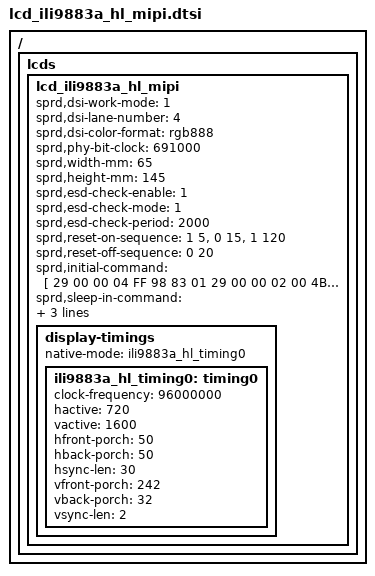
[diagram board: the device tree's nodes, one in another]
/ {
	fragment {
		target-path = "/";
		__overlay__ {
			lcds {
            lcd_ili9883a_hl_mipi: lcd_ili9883a_hl_mipi {
                sprd,dsi-work-mode = <1>;
                sprd,dsi-lane-number = <4>;
                sprd,dsi-color-format = "rgb888";
        
                sprd,phy-bit-clock = <691000>;
        
                sprd,width-mm = <65>;
                sprd,height-mm = <145>;
                sprd,esd-check-enable = <1>;
                sprd,esd-check-mode = <1>;
                sprd,esd-check-period = <2000>;
        
                sprd,reset-on-sequence = <1 5>, <0 15>, <1 120>;
                sprd,reset-off-sequence = <0 20>;
        
                sprd,initial-command = [
					29 00 00 04 FF 98 83 01 
					29 00 00 02 00 4B 
					29 00 00 02 01 34 
					29 00 00 02 02 58 
					29 00 00 02 03 5E 
					29 00 00 02 08 86 
					29 00 00 02 09 01 
					29 00 00 02 0A 73 
					29 00 00 02 0B 00 
					29 00 00 02 0C 0A 
					29 00 00 02 0D 0A 
					29 00 00 02 0E 00 
					29 00 00 02 0F 00 
					29 00 00 02 28 86 
					29 00 00 02 29 4D 
					29 00 00 02 31 07 
					29 00 00 02 32 00 
					29 00 00 02 33 26 
					29 00 00 02 34 02 
					29 00 00 02 35 09 
					29 00 00 02 36 0B 
					29 00 00 02 37 15 
					29 00 00 02 38 17 
					29 00 00 02 39 11 
					29 00 00 02 3A 13 
					29 00 00 02 3B 01 
					29 00 00 02 3C 2B 
					29 00 00 02 3D 07 
					29 00 00 02 3E 07 
					29 00 00 02 3F 07 
					29 00 00 02 40 07 
					29 00 00 02 41 07 
					29 00 00 02 42 07 
					29 00 00 02 43 07 
					29 00 00 02 44 07 
					29 00 00 02 45 07 
					29 00 00 02 46 07 
					29 00 00 02 47 07 
					29 00 00 02 48 00 
					29 00 00 02 49 26 
					29 00 00 02 4A 02 
					29 00 00 02 4B 08 
					29 00 00 02 4C 0A 
					29 00 00 02 4D 14 
					29 00 00 02 4E 16 
					29 00 00 02 4F 10 
					29 00 00 02 50 12 
					29 00 00 02 51 01 
					29 00 00 02 52 2B 
					29 00 00 02 53 07 
					29 00 00 02 54 07 
					29 00 00 02 55 07 
					29 00 00 02 56 07 
					29 00 00 02 57 07 
					29 00 00 02 58 07 
					29 00 00 02 59 07 
					29 00 00 02 5A 07 
					29 00 00 02 5B 07 
					29 00 00 02 5C 07 
					29 00 00 02 61 07 
					29 00 00 02 62 00 
					29 00 00 02 63 26 
					29 00 00 02 64 02 
					29 00 00 02 65 0A 
					29 00 00 02 66 08 
					29 00 00 02 67 12 
					29 00 00 02 68 10 
					29 00 00 02 69 16 
					29 00 00 02 6A 14 
					29 00 00 02 6B 01 
					29 00 00 02 6C 2B 
					29 00 00 02 6D 07 
					29 00 00 02 6E 07 
					29 00 00 02 6F 07 
					29 00 00 02 70 07 
					29 00 00 02 71 07 
					29 00 00 02 72 07 
					29 00 00 02 73 07 
					29 00 00 02 74 07 
					29 00 00 02 75 07 
					29 00 00 02 76 07 
					29 00 00 02 77 07 
					29 00 00 02 78 00 
					29 00 00 02 79 26 
					29 00 00 02 7A 02 
					29 00 00 02 7B 0B 
					29 00 00 02 7C 09 
					29 00 00 02 7D 13 
					29 00 00 02 7E 11 
					29 00 00 02 7F 17 
					29 00 00 02 80 15 
					29 00 00 02 81 01 
					29 00 00 02 82 2B 
					29 00 00 02 83 07 
					29 00 00 02 84 07 
					29 00 00 02 85 07 
					29 00 00 02 86 07 
					29 00 00 02 87 07 
					29 00 00 02 88 07 
					29 00 00 02 89 07 
					29 00 00 02 8A 07 
					29 00 00 02 8B 07 
					29 00 00 02 8C 07 
					29 00 00 02 B0 33 
					29 00 00 02 B1 33 
					29 00 00 02 B2 00 
					29 00 00 02 B9 10 
					29 00 00 02 BA 30 
					29 00 00 02 D0 01 
					29 00 00 02 D1 00 
					29 00 00 02 E2 00 
					29 00 00 02 E6 22 
					29 00 00 02 E7 54 
					29 00 00 04 FF 98 83 02 
					29 00 00 02 06 57 
					29 00 00 02 0A 5B 
					29 00 00 02 0C 00 
					29 00 00 02 0D 20 
					29 00 00 02 0E 73 
					29 00 00 02 39 05 
					29 00 00 02 3A 20 
					29 00 00 02 3B 73 
					29 00 00 02 3C 7C 
					29 00 00 02 F0 05 
					29 00 00 02 F1 5D 
					29 00 00 02 4A 00 
					29 00 00 02 4D CE 
					29 00 00 04 FF 98 83 05 
					29 00 00 02 03 00 
					29 00 00 02 04 B1 
					29 00 00 02 69 9C 
					29 00 00 02 6A 9C 
					29 00 00 02 6D 8D 
					29 00 00 02 73 93 
					29 00 00 02 79 C9 
					29 00 00 02 7F BB 
					29 00 00 04 FF 98 83 06 
					29 00 00 02 D9 1F 
					29 00 00 02 C0 40 
					29 00 00 02 C1 16 
					29 00 00 04 FF 98 83 08 
					29 00 00 1E E0 00 24 31 58 82 50 B9 E7 11 40 95 67 A6 D9 08 AA 35 63 9B BD FE E8 0C 3A 72 3F 9E CF EC 
					29 00 00 1E E1 00 24 31 58 82 50 B9 E7 11 40 95 67 A6 D9 08 AA 35 63 9B BD FE E8 0C 3A 72 3F 9E CF EC 
					29 00 00 04 FF 98 83 0B 
					29 00 00 02 9A 42 
					29 00 00 02 9B C5 
					29 00 00 02 9C 02 
					29 00 00 02 9D 02 
					29 00 00 02 9E 45 
					29 00 00 02 9F 45 
					29 00 00 02 AB E0 
					29 00 00 04 FF 98 83 0E 
					29 00 00 02 11 4E 
					29 00 00 02 12 02 
					29 00 00 02 13 14 
					29 00 00 02 00 A0 
					29 00 00 04 FF 98 83 00 
					29 00 00 02 35 00 
					13 78 00 01 11  
					13 14 00 01 29  
                ];
                sprd,sleep-in-command = [
                    13 14 00 01 28
                    13 78 00 01 10
                ];
        
                sprd,sleep-out-command = [
                    13 78 00 01 11
                    13 64 00 01 29
                ];
        
                display-timings {
                  native-mode = <&ili9883a_hl_timing0>;
                        ili9883a_hl_timing0: timing0 {
                        clock-frequency = <96000000>;
                        hactive = <720>;
                        vactive = <1600>;
                        hfront-porch = <50>;
                        hback-porch = <50>;
                        hsync-len = <30>;
                        vfront-porch = <242>;
                        vback-porch = <32>;
                        vsync-len = <2>;
                    };
                };
            };
			};
		};
	};
};

